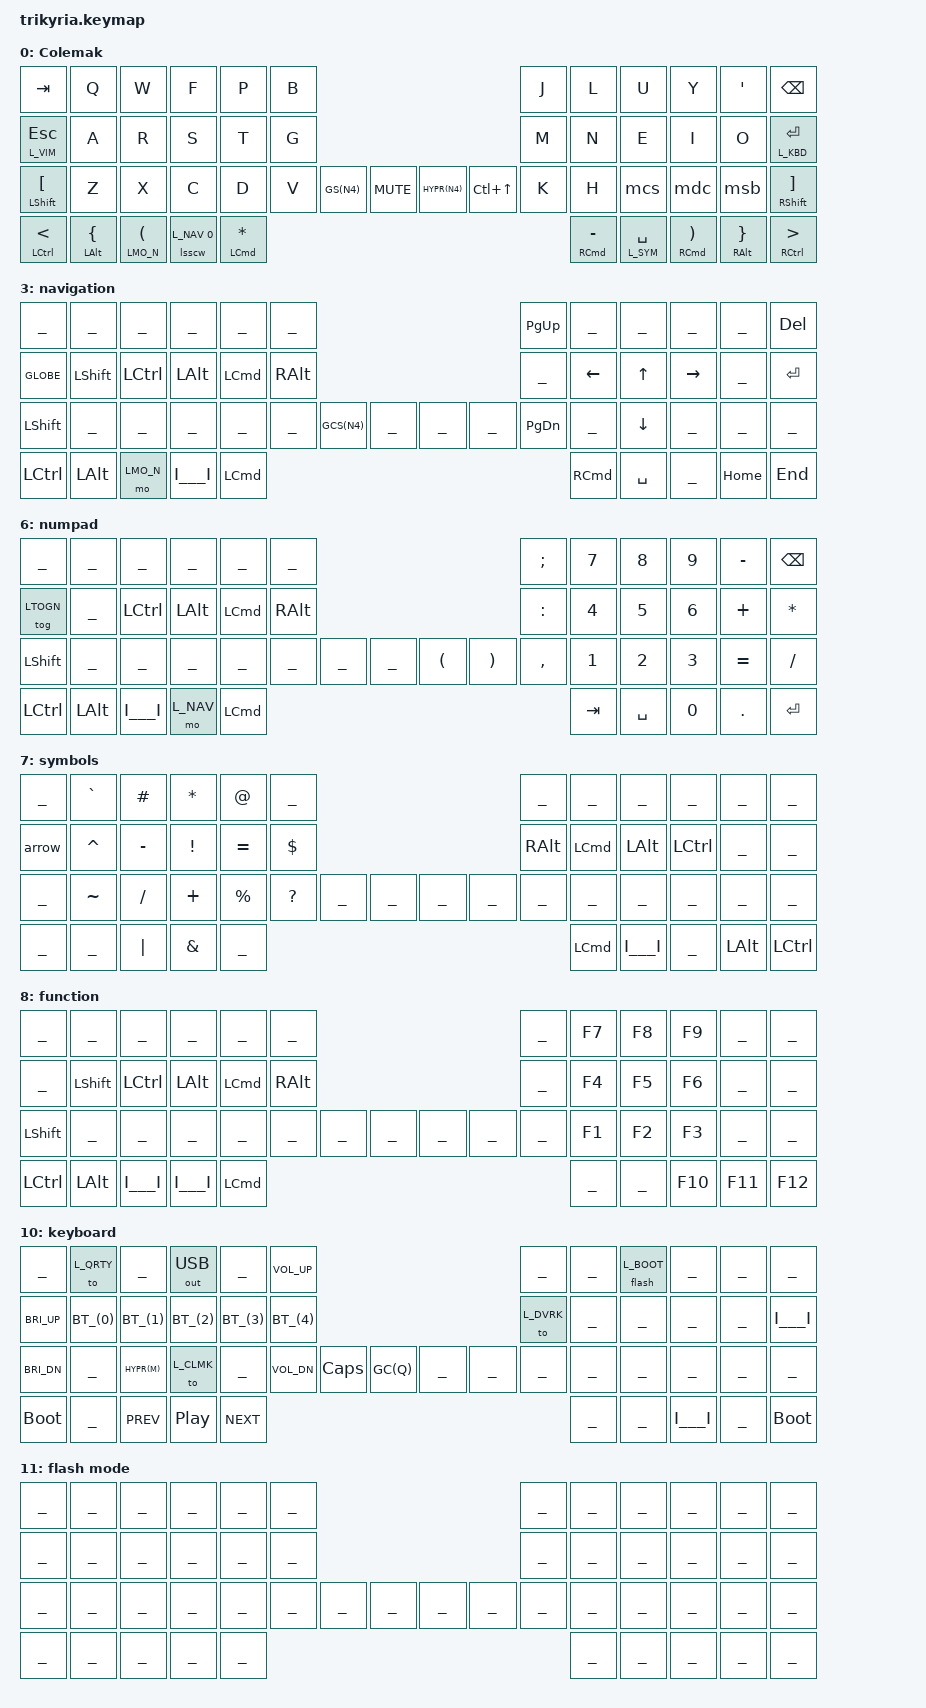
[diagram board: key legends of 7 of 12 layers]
// Kyria rev 3.1 board from splitkb.com
//
// Nice!nano boards on each half, with no rgb strip or display
//
// OLED display with a Xiao BLE as the central dongle

#include <behaviors.dtsi>
#include <dt-bindings/zmk/bt.h>
#include <dt-bindings/zmk/keys.h>
#include <dt-bindings/zmk/outputs.h>
#include "common.keys"

#define L_CLMK 0
#define L_DVRK 1
#define L_QRTY 2
#define L_NAV  3
#define LMO_N  4
#define LTOGN  5
#define L_NUM  6
#define L_SYM  7
#define L_FNC  8
#define L_VIM  9
#define L_KBD  10
#define L_BOOT 11

/ {
    conditional_layers {
        compatible = "zmk,conditional-layers";
        momentary_numpad {
            if-layers = < LMO_N >;
            then-layer = < L_NUM >;
        };
        toggle_numpad {
            if-layers = < LTOGN >;
            then-layer = < L_NUM >;
        };
        func_layer {
            if-layers = <L_NAV LMO_N>;
            then-layer = <L_FNC>;
        };
    };

    keymap {
        compatible = "zmk,keymap";

        colemak {
//                       ┏━━━━━━━━━━━━━━━━━━━━━━━━━┓
            display-name = "Colemak"               ;
//                       ┗━━━━━━━━━━━━━━━━━━━━━━━━━┛
            bindings = <
// ┏━━━━━━━┳━━━━━━━┳━━━━━━━┳━━━━━━━┳━━━━━━━┳━━━━━━━┓                                 ┏━━━━━━━┳━━━━━━━┳━━━━━━━┳━━━━━━━┳━━━━━━━┳━━━━━━━┓
// ┃  TAB  ┃   Q   ┃   W   ┃   F   ┃   P   ┃   B   ┃                                 ┃   J   ┃   L   ┃   U   ┃   Y   ┃  ' "  ┃ BKSPC ┃
    &kp TAB  &kp Q   &kp W   &kp F   &kp P   &kp B                                     &kp J   &kp L   &kp U   &kp Y  &kp SQT &kp BSPC
// ┣━━━━━━━╋━━━━━━━╋━━━━━━━╋━━━━━━━╋━━━━━━━╋━━━━━━━┫                                 ┣━━━━━━━╋━━━━━━━╋━━━━━━━╋━━━━━━━╋━━━━━━━╋━━━━━━━┫
// ┃ESC vim┃   A   ┃   R   ┃   S   ┃   T   ┃   G   ┃                                 ┃   M   ┃   N   ┃   E   ┃   I   ┃   O   ┃RET kbd┃
&lt L_VIM ESC &kp A  &kp R   &kp S   &kp T   &kp G                                     &kp M   &kp N   &kp E   &kp I   &kp O &lt L_KBD RET
// ┣━━━━━━━╋━━━━━━━╋━━━━━━━╋━━━━━━━╋━━━━━━━╋━━━━━━━╋━━━━━━━┳━━━━━━━┓ ┏━━━━━━━┳━━━━━━━╋━━━━━━━╋━━━━━━━╋━━━━━━━╋━━━━━━━╋━━━━━━━╋━━━━━━━┫
// ┃[ shift┃   Z   ┃   X   ┃   C   ┃   D   ┃   V   ┃SCRNSHT┃ MUTE  ┃ ┃LAUNCHP┃MISSION┃   K   ┃   H   ┃  , ;  ┃  . :  ┃  / \  ┃] shift┃
&mt LSHFT LBKT &kp Z &kp X   &kp C   &kp D   &kp V GS(N4) &kp K_MUTE HYPR(N4) &kp LC(UP) &kp K &kp H   &mcs    &mdc    &msb &mt RSHFT RBKT
// ┗━━━━━━━┻━━━━━━━┻━━━┳━━━┻━━━┳━━━┻━━━┳━━━┻━━━┳━━━┻━━━┳━━━┻━━━┳━━━┛ ┗━━━┳━━━┻━━━┳━━━┻━━━┳━━━┻━━━┳━━━┻━━━┳━━━┻━━━┳━━━┻━━━━━━━┻━━━━━━━┛
//                     ┃ < ctrl┃ { opt ┃ ( num ┃ SHIFT ┃ * cmd ┃         ┃ - cmd ┃ SPACE ┃ ) cmd ┃ } opt ┃ > ctrl┃
&mt LCTRL LT &mt LALT LBRC &lt LMO_N LPAR &lsscw L_NAV 0 &mt LCMD STAR &mt RCMD MINUS &lt L_SYM SPC &mt RCMD RPAR &mt RALT RBRC &mt RCTRL GT
//                     ┗━━━━━━━┻━━━━━━━┻━━━━━━━┫  nav  ┣━━━━━━━┛         ┗━━━━━━━┫  sym  ┣━━━━━━━┻━━━━━━━┻━━━━━━━┛
//                                             ┗━━━━━━━┛                         ┗━━━━━━━┛
            >;
        };

        dvorak {
//                       ┏━━━━━━━━━━━━━━━━━━━━━━━━━┓
            display-name = "Dvorak"                ;
//                       ┗━━━━━━━━━━━━━━━━━━━━━━━━━┛
            bindings = <
// ┏━━━━━━━┳━━━━━━━┳━━━━━━━┳━━━━━━━┳━━━━━━━┳━━━━━━━┓                                 ┏━━━━━━━┳━━━━━━━┳━━━━━━━┳━━━━━━━┳━━━━━━━┳━━━━━━━┓
// ┃  TAB  ┃  ' "  ┃  , ;  ┃  . :  ┃   P   ┃   Y   ┃                                 ┃   F   ┃   G   ┃   C   ┃   R   ┃   L   ┃ BKSPC ┃
     I___I  &kp SQT  &mcs    &mdc    I___I   &kp Y                                     &kp F   &kp G   &kp C   &kp R   &kp L   I___I
// ┣━━━━━━━╋━━━━━━━╋━━━━━━━╋━━━━━━━╋━━━━━━━╋━━━━━━━┫                                 ┣━━━━━━━╋━━━━━━━╋━━━━━━━╋━━━━━━━╋━━━━━━━╋━━━━━━━┫
// ┃ESC vim┃   A   ┃   O   ┃   E   ┃   U   ┃   I   ┃                                 ┃   D   ┃   H   ┃   T   ┃   N   ┃   S   ┃RET kbd┃
     I___I   I___I   &kp O   &kp E   &kp U   &kp I                                     &kp D   &kp H   &kp T   &kp N   &kp S   I___I
// ┣━━━━━━━╋━━━━━━━╋━━━━━━━╋━━━━━━━╋━━━━━━━╋━━━━━━━╋━━━━━━━┳━━━━━━━┓ ┏━━━━━━━┳━━━━━━━╋━━━━━━━╋━━━━━━━╋━━━━━━━╋━━━━━━━╋━━━━━━━╋━━━━━━━┫
// ┃[ shift┃  / \  ┃   Q   ┃   J   ┃   K   ┃   X   ┃SCRNSHT┃ MUTE  ┃ ┃LAUNCHP┃MISSION┃   B   ┃   M   ┃   W   ┃   V   ┃   Z   ┃] shift┃
     I___I   I___I   &kp Q   &kp J   &kp K   &kp X   I___I   I___I     I___I   I___I   &kp B   &kp M   &kp W   &kp V   &kp Z   I___I
// ┗━━━━━━━┻━━━━━━━┻━━━┳━━━┻━━━┳━━━┻━━━┳━━━┻━━━┳━━━┻━━━┳━━━┻━━━┳━━━┛ ┗━━━┳━━━┻━━━┳━━━┻━━━┳━━━┻━━━┳━━━┻━━━┳━━━┻━━━┳━━━┻━━━━━━━┻━━━━━━━┛
//                     ┃ < ctrl┃ { opt ┃ ( num ┃ SHIFT ┃ * cmd ┃         ┃ - cmd ┃ SPACE ┃ ) cmd ┃ } opt ┃ > ctrl┃
                         I___I   I___I   I___I   I___I   I___I             I___I   I___I   I___I   I___I   I___I
//                     ┗━━━━━━━┻━━━━━━━┻━━━━━━━┫  nav  ┣━━━━━━━┛         ┗━━━━━━━┫  sym  ┣━━━━━━━┻━━━━━━━┻━━━━━━━┛
//                                             ┗━━━━━━━┛                         ┗━━━━━━━┛
            >;
        };

        qwerty {
//                       ┏━━━━━━━━━━━━━━━━━━━━━━━━━┓
            display-name = "Qwerty"                ;
//                       ┗━━━━━━━━━━━━━━━━━━━━━━━━━┛
            bindings = <
// ┏━━━━━━━┳━━━━━━━┳━━━━━━━┳━━━━━━━┳━━━━━━━┳━━━━━━━┓                                 ┏━━━━━━━┳━━━━━━━┳━━━━━━━┳━━━━━━━┳━━━━━━━┳━━━━━━━┓
// ┃  TAB  ┃   Q   ┃   W   ┃   E   ┃   R   ┃   T   ┃                                 ┃   Y   ┃   U   ┃   I   ┃   O   ┃   P   ┃ BKSPC ┃
     I___I   I___I   I___I   &kp E   &kp R   &kp T                                     &kp Y   &kp U   &kp I   &kp O   &kp P   I___I
// ┣━━━━━━━╋━━━━━━━╋━━━━━━━╋━━━━━━━╋━━━━━━━╋━━━━━━━┫                                 ┣━━━━━━━╋━━━━━━━╋━━━━━━━╋━━━━━━━╋━━━━━━━╋━━━━━━━┫
// ┃ESC vim┃   A   ┃   S   ┃   D   ┃   F   ┃   G   ┃                                 ┃   H   ┃   J   ┃   K   ┃   L   ┃  ' "  ┃RET kbd┃
     I___I   I___I   &kp S   &kp D   &kp F   I___I                                     &kp H   &kp J   &kp K   &kp L  &kp SQT  I___I
// ┣━━━━━━━╋━━━━━━━╋━━━━━━━╋━━━━━━━╋━━━━━━━╋━━━━━━━╋━━━━━━━┳━━━━━━━┓ ┏━━━━━━━┳━━━━━━━╋━━━━━━━╋━━━━━━━╋━━━━━━━╋━━━━━━━╋━━━━━━━╋━━━━━━━┫
// ┃[ shift┃   Z   ┃   X   ┃   C   ┃   V   ┃   B   ┃SCRNSHT┃ MUTE  ┃ ┃LAUNCHP┃MISSION┃   N   ┃   M   ┃  , ;  ┃  . :  ┃  / \  ┃] shift┃
     I___I   I___I   I___I   I___I   &kp V   &kp B   I___I   I___I     I___I   I___I   &kp N   &kp M   &mcs    &mdc    &msb    I___I
// ┗━━━━━━━┻━━━━━━━┻━━━┳━━━┻━━━┳━━━┻━━━┳━━━┻━━━┳━━━┻━━━┳━━━┻━━━┳━━━┛ ┗━━━┳━━━┻━━━┳━━━┻━━━┳━━━┻━━━┳━━━┻━━━┳━━━┻━━━┳━━━┻━━━━━━━┻━━━━━━━┛
//                     ┃ < ctrl┃ { opt ┃ ( num ┃ SHIFT ┃ * cmd ┃         ┃ - cmd ┃ SPACE ┃ ) cmd ┃ } opt ┃ > ctrl┃
                         I___I   I___I   I___I   I___I   I___I             I___I   I___I   I___I   I___I   I___I
//                     ┗━━━━━━━┻━━━━━━━┻━━━━━━━┫  nav  ┣━━━━━━━┛         ┗━━━━━━━┫  sym  ┣━━━━━━━┻━━━━━━━┻━━━━━━━┛
//                                             ┗━━━━━━━┛                         ┗━━━━━━━┛
            >;
        };

        navigation {
//                       ┏━━━━━━━━━━━━━━━━━━━━━━━━━┓
            display-name = "navigation"            ;
//                       ┗━━━━━━━━━━━━━━━━━━━━━━━━━┛
            bindings = <
// ┏━━━━━━━┳━━━━━━━┳━━━━━━━┳━━━━━━━┳━━━━━━━┳━━━━━━━┓                                 ┏━━━━━━━┳━━━━━━━┳━━━━━━━┳━━━━━━━┳━━━━━━━┳━━━━━━━┓
// ┃       ┃       ┃       ┃       ┃       ┃       ┃                                 ┃ PG UP ┃       ┃       ┃       ┃       ┃  DEL  ┃
      ___     ___     ___     ___     ___     ___                                    &kp PG_UP  ___     ___     ___     ___   &kp DEL
// ┣━━━━━━━╋━━━━━━━╋━━━━━━━╋━━━━━━━╋━━━━━━━╋━━━━━━━┫                                 ┣━━━━━━━╋━━━━━━━╋━━━━━━━╋━━━━━━━╋━━━━━━━╋━━━━━━━┫
// ┃ globe ┃ shift ┃  ctrl ┃  opt  ┃  cmd  ┃  alt  ┃                                 ┃       ┃ LEFT  ┃  UP   ┃ RIGHT ┃       ┃ ENTER ┃
&kp GLOBE &kp LSHFT &kp LCTRL &kp LALT &kp LCMD &kp RALT                                ___  &kp LEFT &kp UP &kp RIGHT  ___   &kp RET
// ┣━━━━━━━╋━━━━━━━╋━━━━━━━╋━━━━━━━╋━━━━━━━╋━━━━━━━╋━━━━━━━┳━━━━━━━┓ ┏━━━━━━━┳━━━━━━━╋━━━━━━━╋━━━━━━━╋━━━━━━━╋━━━━━━━╋━━━━━━━╋━━━━━━━┫
// ┃ shift ┃       ┃       ┃       ┃       ┃       ┃SCRNCP ┃       ┃ ┃       ┃       ┃ PG DN ┃       ┃ DOWN  ┃       ┃       ┃       ┃
   &kp LSHFT  ___     ___     ___     ___     ___   GCS(N4)   ___       ___     ___  &kp PG_DN  ___  &kp DOWN   ___     ___     ___
// ┗━━━━━━━┻━━━━━━━┻━━━┳━━━┻━━━┳━━━┻━━━┳━━━┻━━━┳━━━┻━━━┳━━━┻━━━┳━━━┛ ┗━━━┳━━━┻━━━┳━━━┻━━━┳━━━┻━━━┳━━━┻━━━┳━━━┻━━━┳━━━┻━━━━━━━┻━━━━━━━┛
//                     ┃ ctrl  ┃  opt  ┃  fnc  ┃  ###  ┃  cmd  ┃         ┃  cmd  ┃ SPACE ┃       ┃ HOME  ┃  END  ┃
                    &kp LCTRL &kp LALT &mo LMO_N I___I &kp LCMD          &kp RCMD &kp SPC   ___  &kp HOME &kp END
//                     ┗━━━━━━━┻━━━━━━━┻━━━━━━━┫  ###  ┣━━━━━━━┛         ┗━━━━━━━┫       ┣━━━━━━━┻━━━━━━━┻━━━━━━━┛
//                                             ┗━━━━━━━┛                         ┗━━━━━━━┛
            >;
        };

        momentary_numpad {
//          This layer only exists as a workaround to trigger the num layer through two mechanisms, &mo and &tog
//          The real magic for it happens in conditional layers
            bindings = < ___ >;
        };

        toggle_numpad {
//          This layer only exists as a workaround to trigger the num layer through two mechanisms, &mo and &tog
//          The real magic for it happens in conditional layers
            bindings = < ___ >;
        };

        numpad {
//                       ┏━━━━━━━━━━━━━━━━━━━━━━━━━┓
            display-name = "numpad"                ;
//                       ┗━━━━━━━━━━━━━━━━━━━━━━━━━┛
            bindings = <
// ┏━━━━━━━┳━━━━━━━┳━━━━━━━┳━━━━━━━┳━━━━━━━┳━━━━━━━┓                                 ┏━━━━━━━┳━━━━━━━┳━━━━━━━┳━━━━━━━┳━━━━━━━┳━━━━━━━┓
// ┃       ┃       ┃       ┃       ┃       ┃       ┃                                 ┃   ;   ┃   7   ┃   8   ┃   9   ┃   -   ┃ BKSPC ┃
      ___     ___     ___     ___     ___     ___                                    &kp SEMI &kp N7 &kp N8  &kp N9 &kp MINUS &kp BSPC
// ┣━━━━━━━╋━━━━━━━╋━━━━━━━╋━━━━━━━╋━━━━━━━╋━━━━━━━┫                                 ┣━━━━━━━╋━━━━━━━╋━━━━━━━╋━━━━━━━╋━━━━━━━╋━━━━━━━┫
// ┃ TOGGL ┃       ┃  ctrl ┃  opt  ┃  cmd  ┃  alt  ┃                                 ┃   :   ┃   4   ┃   5   ┃   6   ┃   +   ┃   *   ┃
  &tog LTOGN ___ &kp LCTRL &kp LALT &kp LCMD &kp RALT                                &kp COLON &kp N4 &kp N5  &kp N6 &kp PLUS &kp STAR
// ┣━━━━━━━╋━━━━━━━╋━━━━━━━╋━━━━━━━╋━━━━━━━╋━━━━━━━╋━━━━━━━┳━━━━━━━┓ ┏━━━━━━━┳━━━━━━━╋━━━━━━━╋━━━━━━━╋━━━━━━━╋━━━━━━━╋━━━━━━━╋━━━━━━━┫
// ┃ shift ┃       ┃       ┃       ┃       ┃       ┃       ┃       ┃ ┃   (   ┃   )   ┃   ,   ┃   1   ┃   2   ┃   3   ┃   =   ┃   /   ┃
   &kp LSHFT  ___     ___     ___     ___     ___     ___     ___   &kp LPAR &kp RPAR &kp COMMA &kp N1 &kp N2 &kp N3 &kp EQUAL &kp SLASH
// ┗━━━━━━━┻━━━━━━━┻━━━┳━━━┻━━━┳━━━┻━━━┳━━━┻━━━┳━━━┻━━━┳━━━┻━━━┳━━━┛ ┗━━━┳━━━┻━━━┳━━━┻━━━┳━━━┻━━━┳━━━┻━━━┳━━━┻━━━┳━━━┻━━━━━━━┻━━━━━━━┛
//                     ┃ ctrl  ┃  opt  ┃  ###  ┃       ┃  cmd  ┃         ┃  TAB  ┃ SPACE ┃   0   ┃   .   ┃ ENTER ┃
                      &kp LCTRL &kp LALT I___I &mo L_NAV &kp LCMD         &kp TAB &kp SPC  &kp N0 &kp DOT &kp RET
//                     ┗━━━━━━━┻━━━━━━━┻━━━━━━━┫  fnc  ┣━━━━━━━┛         ┗━━━━━━━┫       ┣━━━━━━━┻━━━━━━━┻━━━━━━━┛
//                                             ┗━━━━━━━┛                         ┗━━━━━━━┛
            >;
        };

        symbols {
//                       ┏━━━━━━━━━━━━━━━━━━━━━━━━━┓
            display-name = "symbols"               ;
//                       ┗━━━━━━━━━━━━━━━━━━━━━━━━━┛
            bindings = <
// ┏━━━━━━━┳━━━━━━━┳━━━━━━━┳━━━━━━━┳━━━━━━━┳━━━━━━━┓                                 ┏━━━━━━━┳━━━━━━━┳━━━━━━━┳━━━━━━━┳━━━━━━━┳━━━━━━━┓
// ┃       ┃   `   ┃   #   ┃   *   ┃   @   ┃       ┃                                 ┃       ┃       ┃       ┃       ┃       ┃       ┃
      ___  &kp GRAVE &kp HASH &kp STAR &kp AT ___                                       ___     ___     ___     ___     ___     ___
// ┣━━━━━━━╋━━━━━━━╋━━━━━━━╋━━━━━━━╋━━━━━━━╋━━━━━━━┫                                 ┣━━━━━━━╋━━━━━━━╋━━━━━━━╋━━━━━━━╋━━━━━━━╋━━━━━━━┫
// ┃  =>   ┃   ^   ┃   -   ┃   !   ┃   =   ┃   $   ┃                                 ┃  alt  ┃  cmd  ┃  opt  ┃ ctrl  ┃       ┃       ┃
&arrow &kp CARET &kp MINUS &kp EXCL &kp EQUAL &kp DLLR                               &kp RALT &kp LCMD &kp LALT &kp LCTRL ___   ___
// ┣━━━━━━━╋━━━━━━━╋━━━━━━━╋━━━━━━━╋━━━━━━━╋━━━━━━━╋━━━━━━━┳━━━━━━━┓ ┏━━━━━━━┳━━━━━━━╋━━━━━━━╋━━━━━━━╋━━━━━━━╋━━━━━━━╋━━━━━━━╋━━━━━━━┫
// ┃       ┃   ~   ┃   /   ┃   +   ┃   %   ┃   ?   ┃       ┃       ┃ ┃       ┃       ┃       ┃       ┃       ┃       ┃       ┃       ┃
    ___ &kp TILDE &kp SLASH &kp PLUS &kp PRCNT &kp QMARK ___  ___       ___     ___     ___     ___     ___     ___     ___     ___
// ┗━━━━━━━┻━━━━━━━┻━━━┳━━━┻━━━┳━━━┻━━━┳━━━┻━━━┳━━━┻━━━┳━━━┻━━━┳━━━┛ ┗━━━┳━━━┻━━━┳━━━┻━━━┳━━━┻━━━┳━━━┻━━━┳━━━┻━━━┳━━━┻━━━━━━━┻━━━━━━━┛
//                     ┃       ┃       ┃   |   ┃   &   ┃   _   ┃         ┃  cmd  ┃  ###  ┃       ┃  opt  ┃ ctrl  ┃
                          ___     ___ &kp PIPE &kp AMPS &kp UNDER        &kp LCMD  I___I    ___  &kp LALT &kp LCTRL
//                     ┗━━━━━━━┻━━━━━━━┻━━━━━━━┫       ┣━━━━━━━┛         ┗━━━━━━━┫  ###  ┣━━━━━━━┻━━━━━━━┻━━━━━━━┛
//                                             ┗━━━━━━━┛                         ┗━━━━━━━┛
            >;
        };

        function {
//                       ┏━━━━━━━━━━━━━━━━━━━━━━━━━┓
            display-name = "function"              ;
//                       ┗━━━━━━━━━━━━━━━━━━━━━━━━━┛
            bindings = <
// ┏━━━━━━━┳━━━━━━━┳━━━━━━━┳━━━━━━━┳━━━━━━━┳━━━━━━━┓                                 ┏━━━━━━━┳━━━━━━━┳━━━━━━━┳━━━━━━━┳━━━━━━━┳━━━━━━━┓
// ┃       ┃       ┃       ┃       ┃       ┃       ┃                                 ┃       ┃  F7   ┃  F8   ┃  F9   ┃       ┃       ┃
      ___     ___     ___     ___     ___     ___                                       ___    &kp F7  &kp F8  &kp F9   ___     ___
// ┣━━━━━━━╋━━━━━━━╋━━━━━━━╋━━━━━━━╋━━━━━━━╋━━━━━━━┫                                 ┣━━━━━━━╋━━━━━━━╋━━━━━━━╋━━━━━━━╋━━━━━━━╋━━━━━━━┫
// ┃       ┃ shift ┃  ctrl ┃  opt  ┃  cmd  ┃  alt  ┃                                 ┃       ┃  F4   ┃  F5   ┃  F6   ┃       ┃       ┃
   ___ &kp LSHFT &kp LCTRL &kp LALT &kp LCMD &kp RALT                                   ___    &kp F4  &kp F5  &kp F6   ___     ___
// ┣━━━━━━━╋━━━━━━━╋━━━━━━━╋━━━━━━━╋━━━━━━━╋━━━━━━━╋━━━━━━━┳━━━━━━━┓ ┏━━━━━━━┳━━━━━━━╋━━━━━━━╋━━━━━━━╋━━━━━━━╋━━━━━━━╋━━━━━━━╋━━━━━━━┫
// ┃ shift ┃       ┃       ┃       ┃       ┃       ┃       ┃       ┃ ┃       ┃       ┃       ┃  F1   ┃  F2   ┃  F3   ┃       ┃       ┃
   &kp LSHFT  ___     ___     ___     ___     ___     ___     ___       ___     ___     ___    &kp F1  &kp F2  &kp F3   ___     ___
// ┗━━━━━━━┻━━━━━━━┻━━━┳━━━┻━━━┳━━━┻━━━┳━━━┻━━━┳━━━┻━━━┳━━━┻━━━┳━━━┛ ┗━━━┳━━━┻━━━┳━━━┻━━━┳━━━┻━━━┳━━━┻━━━┳━━━┻━━━┳━━━┻━━━━━━━┻━━━━━━━┛
//                     ┃ ctrl  ┃  opt  ┃  ###  ┃  ###  ┃  cmd  ┃         ┃       ┃       ┃  F10  ┃  F11  ┃  F12  ┃
                      &kp LCTRL &kp LALT I___I   I___I &kp LCMD             ___     ___   &kp F10 &kp F11 &kp F12
//                     ┗━━━━━━━┻━━━━━━━┻━━━━━━━┫  ###  ┣━━━━━━━┛         ┗━━━━━━━┫       ┣━━━━━━━┻━━━━━━━┻━━━━━━━┛
//                                             ┗━━━━━━━┛                         ┗━━━━━━━┛
            >;
        };


        vim {
//                       ┏━━━━━━━━━━━━━━━━━━━━━━━━━┓
            display-name = "vim & tmux"            ;
//                       ┗━━━━━━━━━━━━━━━━━━━━━━━━━┛
            bindings = <
// ┏━━━━━━━┳━━━━━━━┳━━━━━━━┳━━━━━━━┳━━━━━━━┳━━━━━━━┓                                 ┏━━━━━━━┳━━━━━━━┳━━━━━━━┳━━━━━━━┳━━━━━━━┳━━━━━━━┓
// ┃       ┃       ┃       ┃ dongl ┃       ┃       ┃                                 ┃       ┃ tab 7 ┃ tab 8 ┃ tab 9 ┃       ┃ quit! ┃
      ___     ___    ___ &flash L_BOOT ___    ___                                       ___ &vtab N7 &vtab N8 &vtab N9  ___    &vimQ
// ┣━━━━━━━╋━━━━━━━╋━━━━━━━╋━━━━━━━╋━━━━━━━╋━━━━━━━┫                                 ┣━━━━━━━╋━━━━━━━╋━━━━━━━╋━━━━━━━╋━━━━━━━╋━━━━━━━┫
// ┃  ###  ┃       ┃       ┃       ┃       ┃       ┃                                 ┃ tmux- ┃ tab 4 ┃ tab 5 ┃ tab 6 ┃       ┃       ┃
     I___I    ___     ___     ___     ___     ___                                   &kp TMUX &vtab N4 &vtab N5 &vtab N6 ___     ___
// ┣━━━━━━━╋━━━━━━━╋━━━━━━━╋━━━━━━━╋━━━━━━━╋━━━━━━━╋━━━━━━━┳━━━━━━━┓ ┏━━━━━━━┳━━━━━━━╋━━━━━━━╋━━━━━━━╋━━━━━━━╋━━━━━━━╋━━━━━━━╋━━━━━━━┫
// ┃       ┃       ┃       ┃       ┃       ┃       ┃       ┃       ┃ ┃ t bye ┃ tname ┃ t tab ┃ tab 1 ┃ tab 2 ┃ tab 3 ┃       ┃ exit  ┃
      ___     ___     ___     ___     ___     ___     ___     ___    &tmux D &tmux A &tmux N &vtab N1 &vtab N2 &vtab N3 ___   &vldr Q
// ┗━━━━━━━┻━━━━━━━┻━━━┳━━━┻━━━┳━━━┻━━━┳━━━┻━━━┳━━━┻━━━┳━━━┻━━━┳━━━┛ ┗━━━┳━━━┻━━━┳━━━┻━━━┳━━━┻━━━┳━━━┻━━━┳━━━┻━━━┳━━━┻━━━━━━━┻━━━━━━━┛
//                     ┃ flash ┃       ┃       ┃       ┃       ┃         ┃ save  ┃ tmux  ┃ tab10 ┃       ┃       ┃
                      &bootloader ___     ___     ___     ___             &vldr W &tmux C &vtab N0  ___     ___
//                     ┗━━━━━━━┻━━━━━━━┻━━━━━━━┫       ┣━━━━━━━┛         ┗━━━━━━━┫  new  ┣━━━━━━━┻━━━━━━━┻━━━━━━━┛
//                                             ┗━━━━━━━┛                         ┗━━━━━━━┛
            >;
        };

        keyboard {
//                       ┏━━━━━━━━━━━━━━━━━━━━━━━━━┓
            display-name = "keyboard"              ;
//                       ┗━━━━━━━━━━━━━━━━━━━━━━━━━┛
            bindings = <
// ┏━━━━━━━┳━━━━━━━┳━━━━━━━┳━━━━━━━┳━━━━━━━┳━━━━━━━┓                                 ┏━━━━━━━┳━━━━━━━┳━━━━━━━┳━━━━━━━┳━━━━━━━┳━━━━━━━┓
// ┃       ┃ qwrty ┃       ┃  USB  ┃       ┃ vol + ┃                                 ┃       ┃       ┃ dongl ┃       ┃       ┃       ┃
      ___ &to L_QRTY  ___ &out OUT_USB ___   VOL_UP                                     ___    ___ &flash L_BOOT ___    ___     ___
// ┣━━━━━━━╋━━━━━━━╋━━━━━━━╋━━━━━━━╋━━━━━━━╋━━━━━━━┫                                 ┣━━━━━━━╋━━━━━━━╋━━━━━━━╋━━━━━━━╋━━━━━━━╋━━━━━━━┫
// ┃ brt + ┃  BT1  ┃  BT2  ┃  BT3  ┃  BT4  ┃  BT5  ┃                                 ┃ dvork ┃       ┃       ┃       ┃       ┃  ###  ┃
     BRI_UP  BT_(0)  BT_(1)  BT_(2)  BT_(3)  BT_(4)                                 &to L_DVRK  ___     ___     ___     ___    I___I
// ┣━━━━━━━╋━━━━━━━╋━━━━━━━╋━━━━━━━╋━━━━━━━╋━━━━━━━╋━━━━━━━┳━━━━━━━┓ ┏━━━━━━━┳━━━━━━━╋━━━━━━━╋━━━━━━━╋━━━━━━━╋━━━━━━━╋━━━━━━━╋━━━━━━━┫
// ┃ brt - ┃       ┃micmute┃ colmk ┃       ┃ vol - ┃CAPSLOK┃scrnlok┃ ┃       ┃       ┃       ┃       ┃       ┃       ┃       ┃       ┃
     BRI_DN   ___  HYPR(M) &to L_CLMK ___    VOL_DN &kp CAPS GC(Q)      ___     ___     ___     ___     ___     ___     ___     ___
// ┗━━━━━━━┻━━━━━━━┻━━━┳━━━┻━━━┳━━━┻━━━┳━━━┻━━━┳━━━┻━━━┳━━━┻━━━┳━━━┛ ┗━━━┳━━━┻━━━┳━━━┻━━━┳━━━┻━━━┳━━━┻━━━┳━━━┻━━━┳━━━┻━━━━━━━┻━━━━━━━┛
//                     ┃ flash ┃       ┃  prev ┃  play ┃  next ┃         ┃       ┃       ┃  ###  ┃       ┃ flash ┃
                      &bootloader ___ &kp C_PREV &kp C_PLAY_PAUSE &kp C_NEXT ___    ___    I___I    ___ &bootloader
//                     ┗━━━━━━━┻━━━━━━━┻━━━━━━━┫ pause ┣━━━━━━━┛         ┗━━━━━━━┫       ┣━━━━━━━┻━━━━━━━┻━━━━━━━┛
//                                             ┗━━━━━━━┛                         ┗━━━━━━━┛
            >;
        };

        boot {
//                       ┏━━━━━━━━━━━━━━━━━━━━━━━━━┓
            display-name = "flash mode"            ;
//                       ┗━━━━━━━━━━━━━━━━━━━━━━━━━┛
            bindings = <
// ┏━━━━━━━┳━━━━━━━┳━━━━━━━┳━━━━━━━┳━━━━━━━┳━━━━━━━┓                                 ┏━━━━━━━┳━━━━━━━┳━━━━━━━┳━━━━━━━┳━━━━━━━┳━━━━━━━┓
// ┃       ┃       ┃       ┃       ┃       ┃       ┃                                 ┃       ┃       ┃       ┃       ┃       ┃       ┃
      ___     ___     ___     ___     ___     ___                                       ___     ___     ___     ___     ___     ___
// ┣━━━━━━━╋━━━━━━━╋━━━━━━━╋━━━━━━━╋━━━━━━━╋━━━━━━━┫                                 ┣━━━━━━━╋━━━━━━━╋━━━━━━━╋━━━━━━━╋━━━━━━━╋━━━━━━━┫
// ┃       ┃       ┃       ┃       ┃       ┃       ┃                                 ┃       ┃       ┃       ┃       ┃       ┃       ┃
      ___     ___     ___     ___     ___     ___                                       ___     ___     ___     ___     ___     ___
// ┣━━━━━━━╋━━━━━━━╋━━━━━━━╋━━━━━━━╋━━━━━━━╋━━━━━━━╋━━━━━━━┳━━━━━━━┓ ┏━━━━━━━┳━━━━━━━╋━━━━━━━╋━━━━━━━╋━━━━━━━╋━━━━━━━╋━━━━━━━╋━━━━━━━┫
// ┃       ┃       ┃       ┃       ┃       ┃       ┃       ┃       ┃ ┃       ┃       ┃       ┃       ┃       ┃       ┃       ┃       ┃
      ___     ___     ___     ___     ___     ___     ___     ___       ___     ___     ___     ___     ___     ___     ___     ___
// ┗━━━━━━━┻━━━━━━━┻━━━┳━━━┻━━━┳━━━┻━━━┳━━━┻━━━┳━━━┻━━━┳━━━┻━━━┳━━━┛ ┗━━━┳━━━┻━━━┳━━━┻━━━┳━━━┻━━━┳━━━┻━━━┳━━━┻━━━┳━━━┻━━━━━━━┻━━━━━━━┛
//                     ┃       ┃       ┃       ┃       ┃       ┃         ┃       ┃       ┃       ┃       ┃       ┃
                          ___     ___     ___     ___     ___               ___     ___     ___     ___     ___
//                     ┗━━━━━━━┻━━━━━━━┻━━━━━━━┫       ┣━━━━━━━┛         ┗━━━━━━━┫       ┣━━━━━━━┻━━━━━━━┻━━━━━━━┛
//                                             ┗━━━━━━━┛                         ┗━━━━━━━┛
            >;
        };
    };
};

// vim: expandtab softtabstop=4 shiftwidth=4 filetype=devicetree
